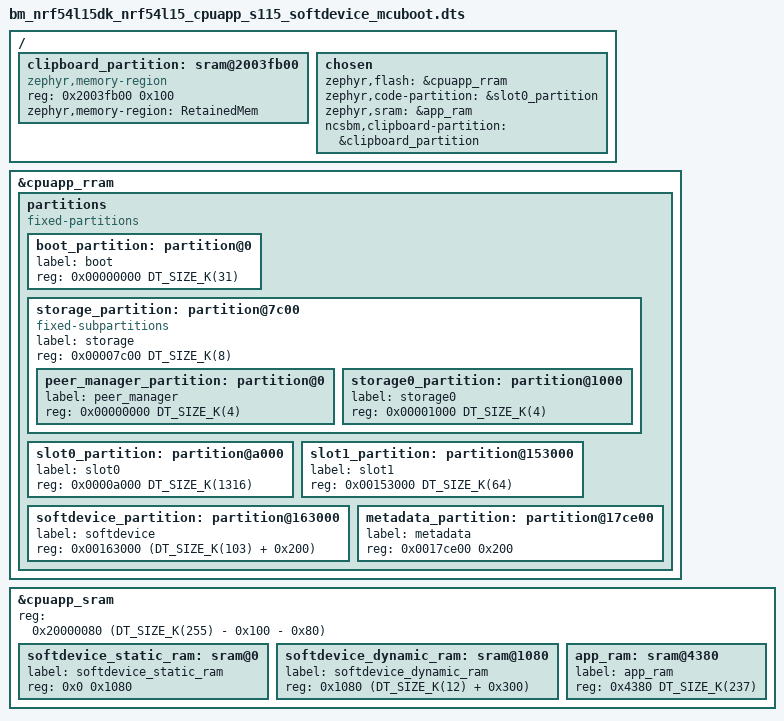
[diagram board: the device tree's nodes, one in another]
/*
 * Copyright (c) 2025 Nordic Semiconductor ASA
 *
 * SPDX-License-Identifier: LicenseRef-Nordic-5-Clause
 */

/dts-v1/;

#include <nordic/nrf54l15_cpuapp.dtsi>
#include "bm_nrf54l15dk_nrf54l15_cpuapp_common.dtsi"

/ {
	/* Placed at the end of SRAM, but adjusted to 1kB boundary
	 * (leaving 512 bytes as unused at the end)
	 */
	clipboard_partition: sram@2003fb00 {
		compatible = "zephyr,memory-region", "mmio-sram";
		reg = <0x2003fb00 0x100>;
		zephyr,memory-region = "RetainedMem";
		status = "okay";
	};

	chosen {
		zephyr,flash = &cpuapp_rram;
		zephyr,code-partition = &slot0_partition;
		zephyr,sram = &app_ram;
		ncsbm,clipboard-partition = &clipboard_partition;
	};
};

&cpuapp_rram {
	status = "okay";

	partitions {
		compatible = "fixed-partitions";
		#address-cells = <1>;
		#size-cells = <1>;

		boot_partition: partition@0 {
			label = "boot";
			reg = <0x00000000 DT_SIZE_K(31)>;
		};

		storage_partition: partition@7c00 {
			compatible = "fixed-subpartitions";
			label = "storage";
			reg = <0x00007c00 DT_SIZE_K(8)>;
			ranges = <0x0 0x7c00 DT_SIZE_K(8)>;
			#address-cells = <1>;
			#size-cells = <1>;

			peer_manager_partition: partition@0 {
				label = "peer_manager";
				reg = <0x00000000 DT_SIZE_K(4)>;
			};

			storage0_partition: partition@1000 {
				label = "storage0";
				reg = <0x00001000 DT_SIZE_K(4)>;
			};
		};

		/* Area from 0x9c00 to 0xa000 is unused due to alignment */

		slot0_partition: partition@a000 {
			label = "slot0";
			reg = <0x0000a000 DT_SIZE_K(1316)>;
		};

		slot1_partition: partition@153000 {
			label = "slot1";
			reg = <0x00153000 DT_SIZE_K(64)>;
		};

		softdevice_partition: partition@163000 {
			label = "softdevice";
			reg = <0x00163000 (DT_SIZE_K(103) + 0x200)>;
		};

		metadata_partition: partition@17ce00 {
			label = "metadata";
			reg = <0x0017ce00 0x200>;
		};
	};
};

&cpuapp_sram {
	status = "okay";

	/* Override setting in bm_nrf54l15dk_nrf54l15_cpuapp_common.dtsi
	 * to adjust sram size to not overlap with retainedmem.
	 * Ignore the extra 512 bytes at the top end.
	 */
	reg = <0x20000080 (DT_SIZE_K(255) - 0x100 - 0x80)>;
	ranges = <0x0 0x20000080 (DT_SIZE_K(255) - 0x100 - 0x80)>;

	softdevice_static_ram: sram@0 {
		label = "softdevice_static_ram";
		reg = <0x0 0x1080>;
	};

	softdevice_dynamic_ram: sram@1080 {
		label = "softdevice_dynamic_ram";
		reg = <0x1080 (DT_SIZE_K(12) + 0x300)>;
	};

	app_ram: sram@4380 {
		label = "app_ram";
		reg = <0x4380 DT_SIZE_K(237)>;
	};
};
